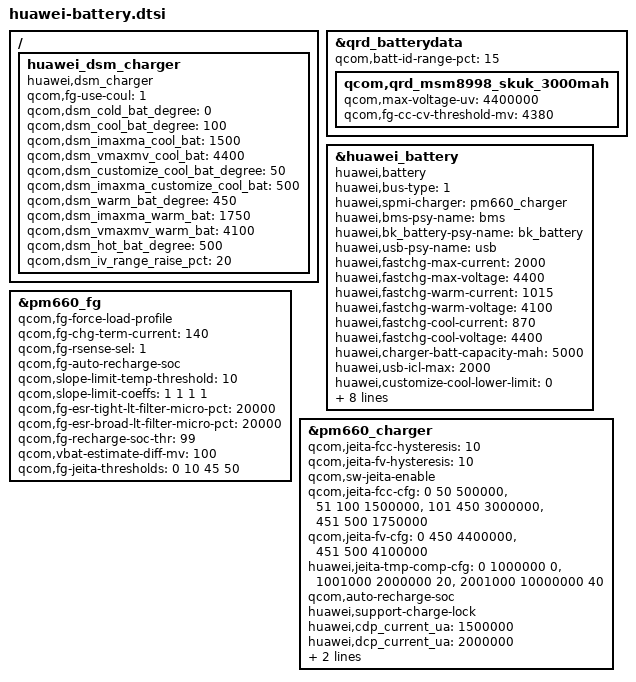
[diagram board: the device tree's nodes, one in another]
&qrd_batterydata {
	       qcom,batt-id-range-pct = <15>;

	        qcom,qrd_msm8998_skuk_3000mah {
		         qcom,max-voltage-uv = <4400000>;
		         qcom,fg-cc-cv-threshold-mv = <4380>;
	        };
	        #include "../HB4073A5ECW_Desay_ATL_4v4_5000mAh.dtsi"
	        #include "../HB4073A5ECW_Scud_GY_4v4_5000mAh.dtsi"
	        #include "../HB4073A5ECW_SWD_Murata_4v4_5000mAh.dtsi"
	        #include "../Huawei_default_battery.dtsi"
       };

		&huawei_battery {
				compatible = "huawei,battery";
				status = "ok";
				huawei,bus-type = <1>;
				huawei,spmi-charger = <&pm660_charger>;
				huawei,bms-psy-name = "bms";
				huawei,bk_battery-psy-name = "bk_battery";
				huawei,usb-psy-name = "usb";
				huawei,fastchg-max-current = <2000>;
				huawei,fastchg-max-voltage = <4400>;
				huawei,fastchg-warm-current = <1015>;
				huawei,fastchg-warm-voltage = <4100>;
				huawei,fastchg-cool-current = <870>;
				huawei,fastchg-cool-voltage = <4400>;
				huawei,charger-batt-capacity-mah = <5000>;
				huawei,usb-icl-max = <2000>;
				huawei,customize-cool-lower-limit = <0>;
				huawei,customize-cool-upper-limit = <50>;
				huawei,fastchg-current-customize-cool-ma = <500>;
				huawei,disable-huawei-func;
				huawei,jeita-hardware-charge-disable;
				huawei,ibus-detect-disable;
				huawei,dump-regs-num = <58>;
				huawei,dump-regs = <
				0x1006 0x1007 0x1009 0x100A 0x100B
				0x100C 0x100D 0x100E 0x1010 0x1042
				0x1050 0x1051 0x1061 0x1063 0x1070
				0x1072 0x1075 0x1090 0x1091 0x1092
				0x10A0 0x10B0 0x10B3 0x10B4 0x10B5
				0x10B6 0x10B7 0x10B8 0x10B9 0x10BA 
				0x10BB 0x10BC 0x10BD 0x10BE 0x10BF
				0x1210 0x1261 0x1306 0x1307 0x1308
				0x1309 0x1310 0x1340 0x1341 0x1343
				0x135B 0x1360 0x1362 0x1363 0x1366
				0x1369 0x1370 0x1381 0x1382 0x1384
				0x1608 0x1609 0x1610
			>;
		};
			&pm660_fg {
			qcom,fg-force-load-profile;
			qcom,fg-chg-term-current = <140>;
			qcom,fg-rsense-sel = <1>;
			qcom,fg-auto-recharge-soc;
			qcom,slope-limit-temp-threshold = <10>;
			qcom,slope-limit-coeffs = <1 1 1 1>;
			qcom,fg-esr-tight-lt-filter-micro-pct = <20000>;
			qcom,fg-esr-broad-lt-filter-micro-pct = <20000>;
			qcom,fg-recharge-soc-thr = <99>;
			qcom,vbat-estimate-diff-mv = <100>;
			qcom,fg-jeita-thresholds = <0 10 45 50>;
		};
		&pm660_charger {
				qcom,jeita-fcc-hysteresis = <10>;
				qcom,jeita-fv-hysteresis = <10>;
				qcom,sw-jeita-enable;
				qcom,jeita-fcc-cfg = <0 50 500000>,
					<51 100 1500000>,
					<101 450 3000000>,
					<451 500 1750000>;
				qcom,jeita-fv-cfg = <0 450 4400000>,
					<451 500 4100000>;
				huawei,jeita-tmp-comp-cfg = <0 1000000 0>,
					<1001000 2000000 20>,
					<2001000 10000000 40>;

				qcom,auto-recharge-soc;
				huawei,support-charge-lock;
				huawei,cdp_current_ua = <1500000>;
				huawei,dcp_current_ua = <2000000>;
				hauwei,float_current_ua = <1000000>;
				huawei,hvdcp_current_ua = <2000000>;
			};
/{
	huawei_dsm_charger: huawei_dsm_charger{
		compatible = "huawei,dsm_charger";
		status = "ok";
		qcom,fg-use-coul = <1>;
		qcom,dsm_cold_bat_degree = <0>;
		qcom,dsm_cool_bat_degree = <100>;
		qcom,dsm_imaxma_cool_bat = <1500>;
		qcom,dsm_vmaxmv_cool_bat = <4400>;
		qcom,dsm_customize_cool_bat_degree = <50>;
		qcom,dsm_imaxma_customize_cool_bat = <500>;
		qcom,dsm_warm_bat_degree = <450>;
		qcom,dsm_imaxma_warm_bat = <1750>;
		qcom,dsm_vmaxmv_warm_bat = <4100>;
		qcom,dsm_hot_bat_degree = <500>;
		qcom,dsm_iv_range_raise_pct = <20>;
	};
};
